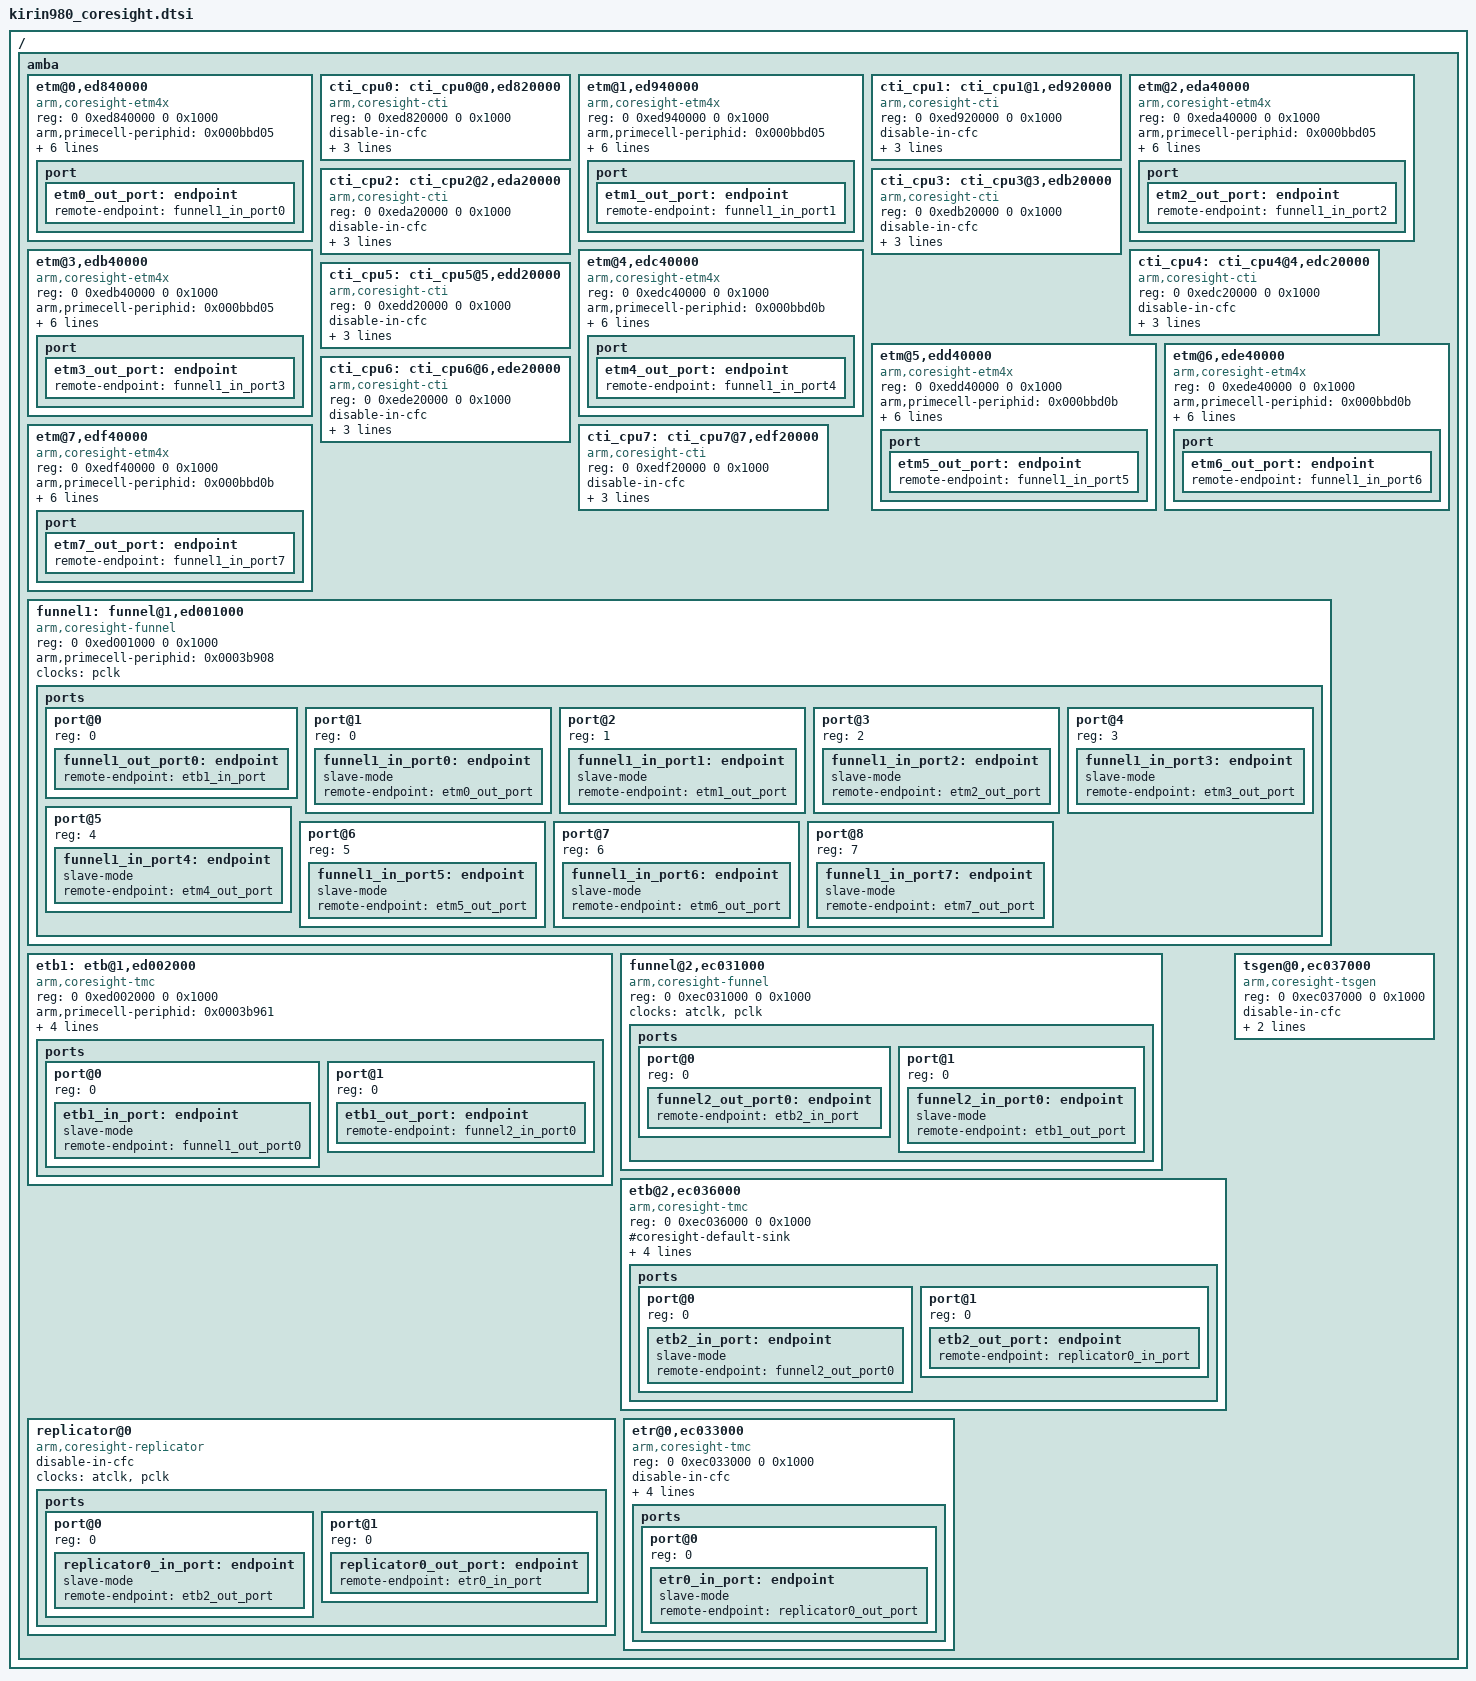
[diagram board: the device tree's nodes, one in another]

/{
	amba {
		/* Ananke cluster internal coresight */
		etm@0,ed840000 {
			compatible = "arm,coresight-etm4x","arm,primecell";
			reg = <0 0xed840000 0 0x1000>;
			arm,primecell-periphid = <0x000bbd05>;
			default_enable;
			clocks = <&pclk>;
			clock-names = "apb_pclk";
			cpu = <&little0>;
			cti_name = "cti_cpu0";
			cluster_etb = <&etb1>;
			cluster_funnel =<&funnel1>;
			port {
				etm0_out_port: endpoint {
					remote-endpoint = <&funnel1_in_port0>;
				};
			};
		};
		cti_cpu0: cti_cpu0@0,ed820000 {
			compatible = "arm,coresight-cti";
			reg = <0 0xed820000 0 0x1000>;

			disable-in-cfc;
			clocks = <&pclk>;
			clock-names = "apb_pclk";
			cpu = <&little0>;
			coresight-name = "cti_cpu0";
		};
		etm@1,ed940000 {
			compatible = "arm,coresight-etm4x","arm,primecell";
			reg = <0 0xed940000 0 0x1000>;
			arm,primecell-periphid = <0x000bbd05>;
			default_enable;
			clocks = <&pclk>;
			clock-names = "apb_pclk";
			cpu = <&little1>;
			cti_name = "cti_cpu1";
			cluster_etb = <&etb1>;
			cluster_funnel =<&funnel1>;
			port {
				etm1_out_port: endpoint {
					remote-endpoint = <&funnel1_in_port1>;
				};
			};

		};
		cti_cpu1: cti_cpu1@1,ed920000 {
			compatible = "arm,coresight-cti";
			reg = <0 0xed920000 0 0x1000>;

			disable-in-cfc;
			clocks = <&pclk>;
			clock-names = "apb_pclk";
			cpu = <&little1>;
			coresight-name = "cti_cpu1";
		};
		etm@2,eda40000 {
			compatible = "arm,coresight-etm4x","arm,primecell";
			reg = <0 0xeda40000 0 0x1000>;
			arm,primecell-periphid = <0x000bbd05>;
			default_enable;
			clocks = <&pclk>;
			clock-names = "apb_pclk";
			cpu = <&little2>;
			cti_name = "cti_cpu2";
			cluster_etb = <&etb1>;
			cluster_funnel =<&funnel1>;
			port {
				etm2_out_port: endpoint {
					remote-endpoint = <&funnel1_in_port2>;
				};
			};
		};
		cti_cpu2: cti_cpu2@2,eda20000 {
			compatible = "arm,coresight-cti";
			reg = <0 0xeda20000 0 0x1000>;

			disable-in-cfc;
			clocks = <&pclk>;
			clock-names = "apb_pclk";
			cpu = <&little2>;
			coresight-name = "cti_cpu2";
		};
		etm@3,edb40000 {
			compatible = "arm,coresight-etm4x","arm,primecell";
			reg = <0 0xedb40000 0 0x1000>;
			arm,primecell-periphid = <0x000bbd05>;
			default_enable;
			clocks = <&pclk>;
			clock-names = "apb_pclk";
			cpu = <&little3>;
			cti_name = "cti_cpu3";
			cluster_etb = <&etb1>;
			cluster_funnel =<&funnel1>;
			port {
				etm3_out_port: endpoint {
					remote-endpoint = <&funnel1_in_port3>;
				};
			};
		};
		cti_cpu3: cti_cpu3@3,edb20000 {
			compatible = "arm,coresight-cti";
			reg = <0 0xedb20000 0 0x1000>;

			disable-in-cfc;
			clocks = <&pclk>;
			clock-names = "apb_pclk";
			cpu = <&little3>;
			coresight-name = "cti_cpu3";
		};

		/* Enyo cluster internal coresight */
		etm@4,edc40000 {
			compatible = "arm,coresight-etm4x","arm,primecell";
			reg = <0 0xedc40000 0 0x1000>;
			arm,primecell-periphid = <0x000bbd0b>;
			default_enable;
			clocks = <&pclk>;
			clock-names = "apb_pclk";
			cpu = <&middle0>;
			cti_name = "cti_cpu4";
			cluster_etb = <&etb1>;
			cluster_funnel =<&funnel1>;
			port {
				etm4_out_port: endpoint {
				remote-endpoint = <&funnel1_in_port4>;
				};
			};
		};
		cti_cpu4: cti_cpu4@4,edc20000 {
			compatible = "arm,coresight-cti";
			reg = <0 0xedc20000 0 0x1000>;
			disable-in-cfc;
			clocks = <&pclk>;
			clock-names = "apb_pclk";
			cpu = <&middle0>;
			coresight-name = "cti_cpu4";
		};
		etm@5,edd40000 {
			compatible = "arm,coresight-etm4x","arm,primecell";
			reg = <0 0xedd40000 0 0x1000>;
			arm,primecell-periphid = <0x000bbd0b>;
			default_enable;
			clocks = <&pclk>;
			clock-names = "apb_pclk";
			cpu = <&middle1>;
			cti_name = "cti_cpu5";
			cluster_etb = <&etb1>;
			cluster_funnel =<&funnel1>;
			port {
				etm5_out_port: endpoint {
				remote-endpoint = <&funnel1_in_port5>;
				};
			};
		};
		cti_cpu5: cti_cpu5@5,edd20000 {
			compatible = "arm,coresight-cti";
			reg = <0 0xedd20000 0 0x1000>;

			disable-in-cfc;
			clocks = <&pclk>;
			clock-names = "apb_pclk";
			cpu = <&middle1>;
			coresight-name = "cti_cpu5";
		};

		etm@6,ede40000 {
			compatible = "arm,coresight-etm4x","arm,primecell";
			reg = <0 0xede40000 0 0x1000>;
			arm,primecell-periphid = <0x000bbd0b>;
			default_enable;
			clocks = <&pclk>;
			clock-names = "apb_pclk";
			cpu = <&big0>;
			cti_name = "cti_cpu6";
			cluster_etb = <&etb1>;
			cluster_funnel =<&funnel1>;
			port {
				etm6_out_port: endpoint {
					remote-endpoint = <&funnel1_in_port6>;
				};
			};
		};
		cti_cpu6: cti_cpu6@6,ede20000 {
			compatible = "arm,coresight-cti";
			reg = <0 0xede20000 0 0x1000>;
			disable-in-cfc;
			clocks = <&pclk>;
			clock-names = "apb_pclk";
			cpu = <&big0>;
			coresight-name = "cti_cpu6";
		};
		etm@7,edf40000 {
			compatible = "arm,coresight-etm4x","arm,primecell";
			reg = <0 0xedf40000 0 0x1000>;
			arm,primecell-periphid = <0x000bbd0b>;
			default_enable;
			clocks = <&pclk>;
			clock-names = "apb_pclk";
			cpu = <&big1>;
			cti_name = "cti_cpu7";
			cluster_etb = <&etb1>;
			cluster_funnel =<&funnel1>;
			port {
				etm7_out_port: endpoint {
					remote-endpoint = <&funnel1_in_port7>;
				};
			};
		};
		cti_cpu7: cti_cpu7@7,edf20000 {
			compatible = "arm,coresight-cti";
			reg = <0 0xedf20000 0 0x1000>;

			disable-in-cfc;
			clocks = <&pclk>;
			clock-names = "apb_pclk";
			cpu = <&big1>;
			coresight-name = "cti_cpu7";
		};

		funnel1:funnel@1,ed001000 {
			compatible = "arm,coresight-funnel","arm,primecell";
			reg = <0 0xed001000 0 0x1000>;
			arm,primecell-periphid = <0x0003b908>;
			clocks = <&pclk>;
			clock-names = "apb_pclk";
			ports {
				#address-cells = <1>;
				#size-cells = <0>;

				/* funnel output port */
				port@0 {
					reg = <0>;
					funnel1_out_port0: endpoint {
						remote-endpoint = <&etb1_in_port>;
					};
				};

				/* funnel input ports */
				port@1 {
					reg = <0>;
					funnel1_in_port0: endpoint {
						slave-mode;
						remote-endpoint = <&etm0_out_port>;
					};
				};

				port@2 {
					reg = <1>;
					funnel1_in_port1: endpoint {
						slave-mode;
						remote-endpoint = <&etm1_out_port>;
					};
				};

				port@3 {
					reg = <2>;
					funnel1_in_port2: endpoint {
						slave-mode;
						remote-endpoint = <&etm2_out_port>;
					};
				};

				port@4 {
					reg = <3>;
					funnel1_in_port3: endpoint {
						slave-mode;
						remote-endpoint = <&etm3_out_port>;
					};
				};

				port@5 {
					reg = <4>;
					funnel1_in_port4: endpoint {
						slave-mode;
						remote-endpoint = <&etm4_out_port>;
					};
				};

				port@6 {
					reg = <5>;
					funnel1_in_port5: endpoint {
						slave-mode;
						remote-endpoint = <&etm5_out_port>;
					};
				};

				port@7 {
					reg = <6>;
					funnel1_in_port6: endpoint {
						slave-mode;
						remote-endpoint = <&etm6_out_port>;
					};
				};

				port@8 {
					reg = <7>;
					funnel1_in_port7: endpoint {
						slave-mode;
						remote-endpoint = <&etm7_out_port>;
					};
				};
			};
		};

		etb1:etb@1,ed002000 {
			compatible = "arm,coresight-tmc","arm,primecell";
			reg = <0 0xed002000 0 0x1000>;
			arm,primecell-periphid = <0x0003b961>;
			arm,buffer-size=<0x4000>;
			#coresight-default-sink;
			clocks = <&pclk>;
			clock-names = "apb_pclk";
			tmc_type = "etf";
			ports {
				#address-cells = <1>;
				#size-cells = <0>;
				/* etb input port */
				port@0 {
					reg = <0>;
					etb1_in_port: endpoint {
						slave-mode;
						remote-endpoint = <&funnel1_out_port0>;
					};
				};
				port@1 {
					reg = <0>;
					etb1_out_port: endpoint {
						remote-endpoint = <&funnel2_in_port0>;
					};
				};
			};
		};

		/* Top coresight config */
		funnel@2,ec031000 {
			compatible = "arm,coresight-funnel","arm,primecell";
			reg = <0 0xec031000 0 0x1000>;

			clocks = <&atclk &pclk>;
			clock-names = "clk_topcs_atclk","apb_pclk";
			ports {
				#address-cells = <1>;
				#size-cells = <0>;

				/* funnel output port */
				port@0 {
					reg = <0>;
					funnel2_out_port0: endpoint {
						remote-endpoint = <&etb2_in_port>;
					};
				};

				/* funnel input ports */
				port@1 {
					reg = <0>;
					funnel2_in_port0: endpoint {
						slave-mode;
						remote-endpoint = <&etb1_out_port>;
					};
				};
			};
		};

		etb@2,ec036000 {
			compatible = "arm,coresight-tmc","arm,primecell";
			reg = <0 0xec036000 0 0x1000>;

			#coresight-default-sink;
			cfc-used-in-tee;
			clocks = <&atclk &pclk>;
			clock-names = "clk_topcs_atclk","apb_pclk";
			tmc_type = "etf";
			arm,buffer-size=<0x1000>;
			ports {
				#address-cells = <1>;
				#size-cells = <0>;

				/* etb input port  */
				port@0 {
					reg = <0>;
					etb2_in_port: endpoint{
						slave-mode;
						remote-endpoint = <&funnel2_out_port0>;
					};
				};

				/* etb out port  */
				port@1 {
					reg = <0>;
					etb2_out_port: endpoint {
						remote-endpoint = <&replicator0_in_port>;
					};
				};
			};
		};

		replicator@0{
			compatible = "arm,coresight-replicator";

			disable-in-cfc;
			clocks = <&atclk &pclk>;
			clock-names = "clk_topcs_atclk","apb_pclk";
			ports {
				#address-cells = <1>;
				#size-cells = <0>;

				/* etb input port  */
				port@0 {
					reg = <0>;
					replicator0_in_port: endpoint{
					slave-mode;
					remote-endpoint = <&etb2_out_port>;
					};
				};
				/* etb out port  */
				port@1 {
					reg = <0>;
					replicator0_out_port: endpoint {
						remote-endpoint = <&etr0_in_port>;
					};
				};
			};
		};

		etr@0,ec033000 {
			compatible = "arm,coresight-tmc","arm,primecell";
			reg = <0 0xec033000 0 0x1000>;

			disable-in-cfc;
			coresight-default-sink;
			clocks = <&atclk &pclk>;
			clock-names = "clk_topcs_atclk","apb_pclk";
			tmc_type = "etr";
			arm,buffer-size=<0x800000>;
			ports {
				#address-cells = <1>;
				#size-cells = <0>;

				/* etr input port  */
				port@0 {
					reg = <0>;
					etr0_in_port: endpoint{
						slave-mode;
						remote-endpoint = <&replicator0_out_port>;
					};
				};
			};
		};

		tsgen@0,ec037000 {
			compatible = "arm,coresight-tsgen";
			reg = <0 0xec037000 0 0x1000>;
			disable-in-cfc;
			clocks = <&clk_gate_time_stamp_gt>;
			clock-names = "clk_timestamp";
			clock-frequency = <29000000>;
		};
	};
};
